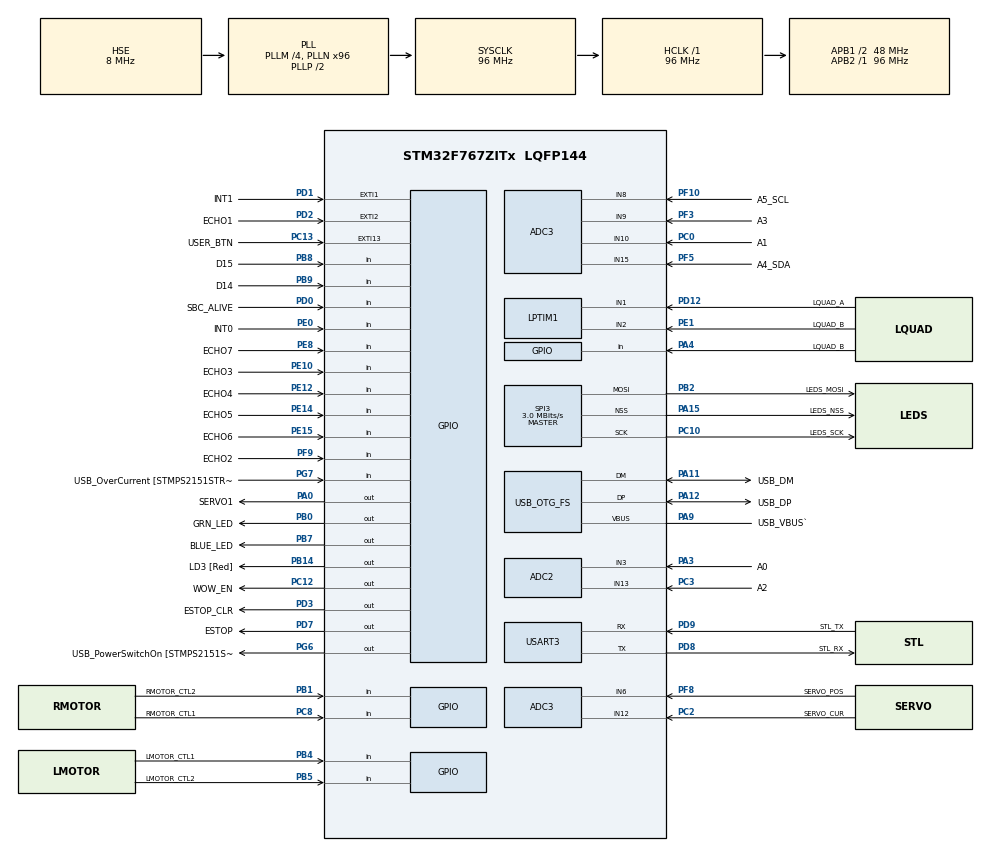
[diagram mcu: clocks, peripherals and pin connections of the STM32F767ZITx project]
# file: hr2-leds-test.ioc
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PD12.GPIO_Label=LQUAD_A
SPI3.Direction=SPI_DIRECTION_2LINES
SPI3.VirtualType=VM_MASTER
PC12.Signal=GPIO_Output
PB14.GPIO_Label=LD3 [Red]
PG6.GPIO_Label=USB_PowerSwitchOn [STMPS2151STR_EN]
PA14.GPIO_Label=SWCLK
PC6.GPIO_Label=RQUAD_A
PA6.GPIO_Label=D12_MISO
PB6.GPIO_Label=SBC_RX
PB13.Signal=UART5_TX
PD6.GPIO_Label=WOW_TX
PG13.Signal=ETH_TXD0
PE6.GPIO_Label=DIO_MOSI
RCC.SYSCLKSource=RCC_SYSCLKSOURCE_PLLCLK
USART3.VirtualMode-Asynchronous=VM_ASYNC
PF7.Signal=UART7_TX
SPI3.VirtualNSS=VM_NSSHARD
RCC.APB2TimFreq_Value=96000000
PB6.Signal=USART1_TX
PC7.Signal=S_TIM8_CH2
PH1/OSC_OUT.Signal=RCC_OSC_OUT
PC3.Signal=ADCx_IN13
PD0.Signal=GPIO_Input
PD8.Signal=USART3_TX
PE5.Signal=SPI4_MISO
PE1.Signal=LPTIM1_IN2
PF10.GPIO_Label=A5_SCL
PB2.Signal=SPI3_MOSI
PF1.GPIO_Label=MISC_SCL
PD1.GPIO_Label=INT1
PB12.GPIO_Label=LIDAR_TX
PC4.GPIO_Label=RMII_RXD0 [LAN8742A-CZ-TR_RXD0]
PE9.Signal=S_TIM1_CH1
PB1.GPIO_Label=RMOTOR_CTL2
PE4.GPIO_Label=DIO_NSS
SH.S_TIM4_CH2.0=TIM4_CH2
PE2.Signal=SPI4_SCK
PF8.Mode=IN6
PA8.Signal=I2C3_SCL
PF3.Signal=ADC3_IN9
PE10.Signal=GPIO_Input
Mcu.Package=LQFP144
PB9.Signal=GPIO_Input
PB1.Signal=GPIO_Input
SPI3.Mode=SPI_MODE_MASTER
PD12.Signal=LPTIM1_IN1
ADC3.Rank-0\#ChannelRegularConversion=1
PA10.Signal=USB_OTG_FS_ID
PE12.GPIO_Label=ECHO4
RCC.APB1TimFreq_Value=96000000
PF10.Mode=IN8
PE10.GPIO_Label=ECHO3
PA4.GPIO_Label=LQUAD_B
PD15.Signal=S_TIM4_CH4
PD9.GPIO_Label=STL_TX
PG9.Signal=USART6_RX
PC13.Signal=GPXTI13
PA9.GPIO_Label=USB_VBUS`
PD3.Signal=GPIO_Output
PE1.Mode=Encoder_mode_occur1
PC2.Signal=ADCx_IN12
PC6.Signal=S_TIM8_CH1
PB11.GPIO_Label=SERVO4
PD7.Signal=GPIO_Output
PD1.Signal=GPXTI1
PA11.GPIO_Label=USB_DM
PC0.Signal=ADCx_IN10
RCC.APB1CLKDivider=RCC_HCLK_DIV2
PG13.GPIO_Label=RMII_TXD0 [LAN8742A-CZ-TR_TXD0]
SH.S_TIM8_CH2.0=TIM8_CH2
PF8.GPIO_Label=SERVO_POS
PB8.GPIO_Label=D15
PE8.GPIO_Label=ECHO7
PA9.Signal=USB_OTG_FS_VBUS
PE9.GPIO_Label=D6_PWM
PD8.Mode=Asynchronous
PB10.Signal=S_TIM2_CH3
PB14.Signal=GPIO_Output
PA5.Signal=SPI1_SCK
PD7.PinState=GPIO_PIN_RESET
SH.S_TIM8_CH1.0=TIM8_CH1
PE1.GPIO_Label=LQUAD_B
PE14.Signal=GPIO_Input
PE15.Signal=GPIO_Input
PB4.GPIO_Label=LMOTOR_CTL1
RCC.PRESCALERUSB=RCC_USBCLKSOURCE_PLL_DIV1_5
PB15.GPIO_Label=SBC_TX
PE8.Signal=GPIO_Input
PG7.GPIO_Label=USB_OverCurrent [STMPS2151STR_FAULT]
PA1.GPIO_Label=RMII_REF_CLK [LAN8742A-CZ-TR_REFCLK0]
PA0/WKUP.GPIO_Label=SERVO1
PA13.Mode=Serial_Wire
PG14.GPIO_Label=D1_TX
PC7.GPIO_Label=RQUAD_B
PA4.Signal=GPIO_Input
PB5.Signal=GPIO_Input
PE13.GPIO_Label=D3_PWM
PD12.Mode=Encoder_mode_occur1
PA5.GPIO_Label=D13_SCK
ADC2.NbrOfConversionFlag=1
PE5.GPIO_Label=DIO_MOSO
PC12.GPIO_Label=WOW_EN
PA11.Signal=USB_OTG_FS_DM
ProjectManager.HeapSize=0x200
PF9.Signal=GPIO_Input
NVIC.PriorityGroup=NVIC_PRIORITYGROUP_4
PF0.GPIO_Label=MISC_SDA
PC3.GPIO_Label=A2
PC15/OSC32_OUT.Signal=RCC_OSC32_OUT
PD2.Signal=GPXTI2
PB0.Signal=GPIO_Output
PC1.Signal=ETH_MDC
PD2.GPIO_Label=ECHO1
Mcu.Family=STM32F7
RCC.CortexFreq_Value=96000000
PG6.Signal=GPIO_Output
ADC2.Channel-0\#ChannelRegularConversion=ADC_CHANNEL_13
PE11.GPIO_Label=D5_PWM
PC10.Signal=SPI3_SCK
RCC.SYSCLKSourceVirtual=RCC_SYSCLKSOURCE_PLLCLK
PB2.GPIO_Speed=GPIO_SPEED_FREQ_VERY_HIGH
PC0.GPIO_Label=A1
PD0.GPIO_Label=SBC_ALIVE
PA11.Mode=Device_Only
PA0/WKUP.Signal=GPIO_Output
PC14/OSC32_IN.Mode=LSE-External-Oscillator
PB0.GPIO_Label=GRN_LED
PC10.GPIO_Speed=GPIO_SPEED_FREQ_VERY_HIGH
PC13.GPIO_Label=USER_BTN
PB13.GPIO_Label=LIDAR_RX
PB11.Signal=S_TIM2_CH4
PB15.Signal=USART1_RX
ADC3.Channel-0\#ChannelRegularConversion=ADC_CHANNEL_9
PD9.Mode=Asynchronous
PG11.Signal=ETH_TX_EN
ProjectManager.StackSize=0x400
PD13.Signal=S_TIM4_CH2
PA15.GPIO_Label=LEDS_NSS
PA12.Signal=USB_OTG_FS_DP
Mcu.UserConstants=MTR_PWM_PERIOD,1280
PH0/OSC_IN.Mode=HSE-External-Clock-Source
RCC.HCLKFreq_Value=96000000
SH.ADCx_IN3.0=ADC2_IN3,IN3
RCC.AHBFreq_Value=96000000
SPI3.DataSize=SPI_DATASIZE_16BIT
RCC.HSE_VALUE=8000000
PA15.Mode=NSS_Signal_Hard_Output
RCC.PLLMUL=RCC_PLL_MUL9
PE13.Signal=S_TIM1_CH3
PF7.GPIO_Label=FPGA_RX
PA14.Mode=Serial_Wire
PC11.GPIO_Label=LEDS_MISO
PA10.GPIO_Label=USB_ID
PB7.Signal=GPIO_Output
PH1/OSC_OUT.Mode=HSE-External-Clock-Source
PE4.Signal=SPI4_NSS
PD7.GPIO_Label=ESTOP
PB7.GPIO_Label=BLUE_LED
PD13.GPIO_Label=LIDAR_PWM
PA6.Signal=SPI1_MISO
PC14/OSC32_IN.Signal=RCC_OSC32_IN
PD5.GPIO_Label=WOW_RX
PA2.GPIO_Label=RMII_MDIO [LAN8742A-CZ-TR_MDIO]
PF5.GPIO_Label=A4_SDA
USB_OTG_FS.VirtualMode=Device_Only
PA15.Signal=SPI3_NSS
PF8.Signal=ADC3_IN6
ADC2.SamplingTime-0\#ChannelRegularConversion=ADC_SAMPLETIME_3CYCLES
PE0.GPIO_Label=INT0
PF5.Signal=ADC3_IN15
PB5.GPIO_Label=LMOTOR_CTL2
PG11.GPIO_Label=RMII_TX_EN [LAN8742A-CZ-TR_TXEN]
PF0.Signal=I2C2_SDA
PC5.Signal=ETH_RXD1
PD3.GPIO_Label=ESTOP_CLR
PE7.Signal=UART7_RX
ADC2.Rank-0\#ChannelRegularConversion=1
PD6.Signal=USART2_RX
PF3.GPIO_Label=A3
PE2.GPIO_Label=DIO_SCK
PC2.GPIO_Label=SERVO_CUR
PB4.Signal=GPIO_Input
PA3.Signal=ADCx_IN3
PB3.GPIO_Label=SERVO2
SH.ADCx_IN13.0=ADC2_IN13,IN13
PD15.GPIO_Label=D9_PWM
PG7.Signal=GPIO_Input
PF3.Mode=IN9
PB9.GPIO_Label=D14
PC10.GPIO_Label=LEDS_SCK
PC9.GPIO_Label=A4_SDA
SH.S_TIM4_CH4.0=TIM4_CH4
PC11.Signal=SPI3_MISO
PC8.Signal=GPIO_Input
PC4.Signal=ETH_RXD0
PC10.Mode=TX_Only_Simplex_Unidirect_Master
PE14.GPIO_Label=ECHO5
PD9.Signal=USART3_RX
PD5.Signal=USART2_TX
PA12.GPIO_Label=USB_DP
PF5.Mode=IN15
PD8.GPIO_Label=STL_RX
PC8.GPIO_Label=RMOTOR_CTL1
PA13.Signal=SYS_JTMS-SWDIO
SH.S_TIM2_CH2.0=TIM2_CH2
PA9.Mode=Activate_VBUS
SH.ADCx_IN12.0=ADC3_IN12,IN12
ADC3.SamplingTime-0\#ChannelRegularConversion=ADC_SAMPLETIME_3CYCLES
SH.S_TIM1_CH1.0=TIM1_CH1
PE15.GPIO_Label=ECHO6
ProjectManager.TargetToolchain=STM32CubeIDE
PB10.GPIO_Label=SERVO3
SH.S_TIM4_CH3.0=TIM4_CH3
RCC.USBFreq_Value=48000000
PF9.GPIO_Label=ECHO2
PE11.Signal=S_TIM1_CH2
PA1.Signal=ETH_REF_CLK
PG9.GPIO_Label=D0_RX
PG14.Signal=USART6_TX
board=NUCLEO-F767ZI
RCC.VCOOutputFreq_Value=192000000
PH0/OSC_IN.Signal=RCC_OSC_IN
RCC.APB2Freq_Value=96000000
SPI3.CalculateBaudRate=3.0 MBits/s
SH.S_TIM1_CH2.0=TIM1_CH2
SH.S_TIM2_CH3.0=TIM2_CH3
PF10.Signal=ADC3_IN8
SPI3.BaudRatePrescaler=SPI_BAUDRATEPRESCALER_16
PC1.GPIO_Label=RMII_MDC [LAN8742A-CZ-TR_MDC]
PD14.GPIO_Label=D10_PWM_NSS
PF1.Signal=I2C2_SCL
PE6.Signal=SPI4_MOSI
Mcu.Name=STM32F767ZITx
PE0.Signal=GPIO_Input
PE7.GPIO_Label=FPGA_TX
PE12.Signal=GPIO_Input
PA2.Signal=ETH_MDIO
PA13.GPIO_Label=SWDIO
PD14.Signal=S_TIM4_CH3
RCC.48MHZClocksFreq_Value=24000000
PB3.Signal=S_TIM2_CH2
RCC.SYSCLKFreq_VALUE=96000000
PA7.GPIO_Label=D11_PWM_MOSI
PA12.Mode=Device_Only
PC5.GPIO_Label=RMII_RXD1 [LAN8742A-CZ-TR_RXD1]
PC15/OSC32_OUT.Mode=LSE-External-Oscillator
PB2.Mode=TX_Only_Simplex_Unidirect_Master
PA15.GPIO_Speed=GPIO_SPEED_FREQ_VERY_HIGH
PA14.Signal=SYS_JTCK-SWCLK
SH.ADCx_IN10.0=ADC3_IN10,IN10
PB2.GPIO_Label=LEDS_MOSI
SH.S_TIM2_CH4.0=TIM2_CH4
SH.S_TIM1_CH3.0=TIM1_CH3
RCC.HSI_VALUE=16000000
PH0/OSC_IN.GPIO_Label=MCO [STM32F103CBT6_PA8]
RCC.PLLQ=4
RCC.PLLM=4
RCC.PLLN=96
PB8.Signal=GPIO_Input
PC9.Signal=I2C3_SDA
RCC.APB1Freq_Value=48000000
ADC3.NbrOfConversionFlag=1
PB12.Signal=UART5_RX
PA3.GPIO_Label=A0
PA7.Signal=SPI1_MOSI

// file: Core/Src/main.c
/* USER CODE BEGIN Header */
/**
  ******************************************************************************
  * @file           : main.c
  * @brief          : Main program body
  ******************************************************************************
  * @attention
  *
  * <h2><center>&copy; Copyright (c) 2021 STMicroelectronics.
  * All rights reserved.</center></h2>
  *
  * This software component is licensed by ST under BSD 3-Clause license,
  * the "License"; You may not use this file except in compliance with the
  * License. You may obtain a copy of the License at:
  *                        opensource.org/licenses/BSD-3-Clause
  *
  ******************************************************************************
  */
/* USER CODE END Header */
#include "main.h"
#include "adc.h"
#include "lptim.h"
#include "spi.h"
#include "usart.h"
#include "usb_otg.h"
#include "gpio.h"

void SystemClock_Config(void);

int main(void)
{

  /* MCU Configuration--------------------------------------------------------*/

  /* Reset of all peripherals, Initializes the Flash interface and the Systick. */
  HAL_Init();

  /* Configure the system clock */
  SystemClock_Config();

  /* Initialize all configured peripherals */
  MX_GPIO_Init();
  MX_USART3_UART_Init();
  MX_USB_OTG_FS_PCD_Init();
  MX_ADC2_Init();
  MX_ADC3_Init();
  MX_LPTIM1_Init();
  MX_SPI3_Init();

  /* Infinite loop */
  /* USER CODE BEGIN WHILE */
  uint16_t leds = 0x8000;

  while (1)
  {
    /* USER CODE END WHILE */

    /* USER CODE BEGIN 3 */
	HAL_SPI_Transmit(&hspi3, (uint8_t *)&leds, 1, 1);
	leds >>= 1;
	if (leds == 0)
	  leds = 0x8000;
	HAL_Delay(100);

  }
  /* USER CODE END 3 */
}

void SystemClock_Config(void)
{
  RCC_OscInitTypeDef RCC_OscInitStruct = {0};
  RCC_ClkInitTypeDef RCC_ClkInitStruct = {0};
  RCC_PeriphCLKInitTypeDef PeriphClkInitStruct = {0};

  /** Configure LSE Drive Capability
  */
  HAL_PWR_EnableBkUpAccess();
  /** Configure the main internal regulator output voltage
  */
  __HAL_RCC_PWR_CLK_ENABLE();
  __HAL_PWR_VOLTAGESCALING_CONFIG(PWR_REGULATOR_VOLTAGE_SCALE3);
  /** Initializes the RCC Oscillators according to the specified parameters
  * in the RCC_OscInitTypeDef structure.
  */
  RCC_OscInitStruct.OscillatorType = RCC_OSCILLATORTYPE_HSE;
  RCC_OscInitStruct.HSEState = RCC_HSE_BYPASS;
  RCC_OscInitStruct.PLL.PLLState = RCC_PLL_ON;
  RCC_OscInitStruct.PLL.PLLSource = RCC_PLLSOURCE_HSE;
  RCC_OscInitStruct.PLL.PLLM = 4;
  RCC_OscInitStruct.PLL.PLLN = 96;
  RCC_OscInitStruct.PLL.PLLP = RCC_PLLP_DIV2;
  RCC_OscInitStruct.PLL.PLLQ = 4;
  if (HAL_RCC_OscConfig(&RCC_OscInitStruct) != HAL_OK)
  {
    Error_Handler();
  }
  /** Activate the Over-Drive mode
  */
  if (HAL_PWREx_EnableOverDrive() != HAL_OK)
  {
    Error_Handler();
  }
  /** Initializes the CPU, AHB and APB buses clocks
  */
  RCC_ClkInitStruct.ClockType = RCC_CLOCKTYPE_HCLK|RCC_CLOCKTYPE_SYSCLK
                              |RCC_CLOCKTYPE_PCLK1|RCC_CLOCKTYPE_PCLK2;
  RCC_ClkInitStruct.SYSCLKSource = RCC_SYSCLKSOURCE_PLLCLK;
  RCC_ClkInitStruct.AHBCLKDivider = RCC_SYSCLK_DIV1;
  RCC_ClkInitStruct.APB1CLKDivider = RCC_HCLK_DIV2;
  RCC_ClkInitStruct.APB2CLKDivider = RCC_HCLK_DIV1;

  if (HAL_RCC_ClockConfig(&RCC_ClkInitStruct, FLASH_LATENCY_3) != HAL_OK)
  {
    Error_Handler();
  }
  PeriphClkInitStruct.PeriphClockSelection = RCC_PERIPHCLK_USART3|RCC_PERIPHCLK_LPTIM1
                              |RCC_PERIPHCLK_CLK48;
  PeriphClkInitStruct.Usart3ClockSelection = RCC_USART3CLKSOURCE_PCLK1;
  PeriphClkInitStruct.Lptim1ClockSelection = RCC_LPTIM1CLKSOURCE_PCLK;
  PeriphClkInitStruct.Clk48ClockSelection = RCC_CLK48SOURCE_PLL;
  if (HAL_RCCEx_PeriphCLKConfig(&PeriphClkInitStruct) != HAL_OK)
  {
    Error_Handler();
  }
}

void Error_Handler(void)
{
  __disable_irq();
  while (1)
  {
  }
}

/************************ (C) COPYRIGHT STMicroelectronics *****END OF FILE****/
